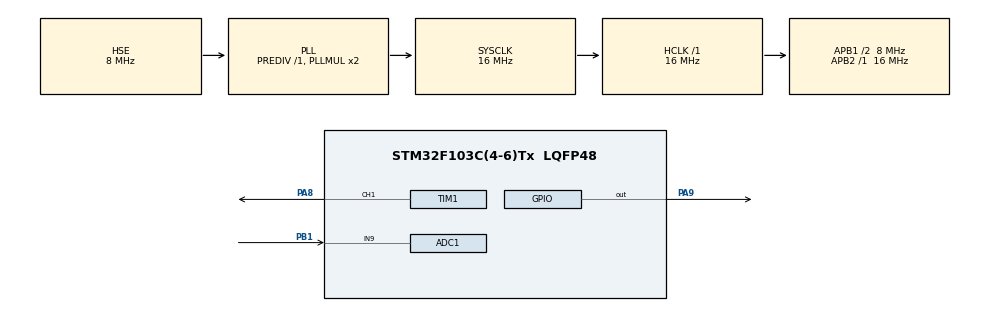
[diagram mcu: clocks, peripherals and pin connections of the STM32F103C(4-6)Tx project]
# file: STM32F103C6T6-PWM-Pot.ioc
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ADC1.Channel-4\#ChannelRegularConversion=ADC_CHANNEL_9
ADC1.ContinuousConvMode=ENABLE
ADC1.NbrOfConversion=1
ADC1.NbrOfConversionFlag=1
ADC1.Rank-4\#ChannelRegularConversion=1
ADC1.SamplingTime-4\#ChannelRegularConversion=ADC_SAMPLETIME_239CYCLES_5
ADC1.master=1
Dma.ADC1.0.Direction=DMA_PERIPH_TO_MEMORY
Dma.ADC1.0.Instance=DMA1_Channel1
Dma.ADC1.0.MemDataAlignment=DMA_MDATAALIGN_WORD
Dma.ADC1.0.MemInc=DMA_MINC_ENABLE
Dma.ADC1.0.Mode=DMA_CIRCULAR
Dma.ADC1.0.PeriphDataAlignment=DMA_PDATAALIGN_WORD
Dma.ADC1.0.PeriphInc=DMA_PINC_DISABLE
Dma.ADC1.0.Priority=DMA_PRIORITY_LOW
Dma.Request0=ADC1
Mcu.Family=STM32F1
Mcu.Name=STM32F103C(4-6)Tx
Mcu.Package=LQFP48
NVIC.DMA1_Channel1_IRQn=true\:0\:0\:false\:false\:true\:false\:true\:true
NVIC.PriorityGroup=NVIC_PRIORITYGROUP_4
PA13.Mode=Serial_Wire
PA13.Signal=SYS_JTMS-SWDIO
PA14.Mode=Serial_Wire
PA14.Signal=SYS_JTCK-SWCLK
PA8.Signal=S_TIM1_CH1
PA9.PinState=GPIO_PIN_SET
PA9.Signal=GPIO_Output
PB1.Signal=ADCx_IN9
PC14-OSC32_IN.Mode=LSE-External-Oscillator
PC14-OSC32_IN.Signal=RCC_OSC32_IN
PC15-OSC32_OUT.Mode=LSE-External-Oscillator
PC15-OSC32_OUT.Signal=RCC_OSC32_OUT
PD0-OSC_IN.Mode=HSE-External-Oscillator
PD0-OSC_IN.Signal=RCC_OSC_IN
PD1-OSC_OUT.Mode=HSE-External-Oscillator
PD1-OSC_OUT.Signal=RCC_OSC_OUT
ProjectManager.HeapSize=0x200
ProjectManager.StackSize=0x400
ProjectManager.TargetToolchain=CMake
RCC.AHBFreq_Value=16000000
RCC.APB1CLKDivider=RCC_HCLK_DIV2
RCC.APB1Freq_Value=8000000
RCC.APB1TimFreq_Value=16000000
RCC.APB2Freq_Value=16000000
RCC.APB2TimFreq_Value=16000000
RCC.HCLKFreq_Value=16000000
RCC.PLLSourceVirtual=RCC_PLLSOURCE_HSE
RCC.SYSCLKFreq_VALUE=16000000
RCC.SYSCLKSource=RCC_SYSCLKSOURCE_PLLCLK
RCC.USBFreq_Value=16000000
SH.ADCx_IN9.0=ADC1_IN9,IN9
SH.S_TIM1_CH1.0=TIM1_CH1,PWM Generation1 CH1
TIM1.Channel-PWM\ Generation1\ CH1=TIM_CHANNEL_1
TIM1.Period=999
TIM1.Prescaler=71
board=custom

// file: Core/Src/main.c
/* USER CODE BEGIN Header */
/**
  ******************************************************************************
  * @file           : main.c
  * @brief          : Main program body
  ******************************************************************************
  * @attention
  *
  * Copyright (c) 2026 STMicroelectronics.
  * All rights reserved.
  *
  * This software is licensed under terms that can be found in the LICENSE file
  * in the root directory of this software component.
  * If no LICENSE file comes with this software, it is provided AS-IS.
  *
  ******************************************************************************
  */
/* USER CODE END Header */
#include "main.h"

/* USER CODE BEGIN PD */
uint32_t adc_dma[1];
/* USER CODE END PD */

ADC_HandleTypeDef hadc1;
DMA_HandleTypeDef hdma_adc1;

TIM_HandleTypeDef htim1;

void SystemClock_Config(void);
static void MX_GPIO_Init(void);
static void MX_DMA_Init(void);
static void MX_TIM1_Init(void);
static void MX_ADC1_Init(void);

/* USER CODE BEGIN 0 */

// ADC dalgalanmalarina ve gurultuye karsi 16 olcum yapip ortalamasini aliyoruz
#define FILTER_SIZE 16

uint32_t sum = 0;
uint16_t buffer[FILTER_SIZE];
uint8_t indexx = 0;

uint16_t FilterADC(uint16_t adc)
{
    sum -= buffer[indexx];
    buffer[indexx] = adc;
    sum += adc;

    indexx++;
    if(indexx >= FILTER_SIZE)
        indexx = 0;

    return sum / FILTER_SIZE;
}

//ADC icin 1k Potansiyometre kullan 1k daha stabil 10k fazla ziplama yapiyor
void HAL_SYSTICK_Callback(void)
{
    uint16_t adc = FilterADC(adc_dma[0]);
    uint32_t ccr = (adc * 1000) / 4095;

    // Alt eşik: bu değerin altını tamamen 0 kabul et
    if (ccr < 5 )
        ccr = 0;

    __HAL_TIM_SET_COMPARE(&htim1, TIM_CHANNEL_1, ccr);
}

/* USER CODE END 0 */

int main(void)
{

  /* MCU Configuration--------------------------------------------------------*/

  /* Reset of all peripherals, Initializes the Flash interface and the Systick. */
  HAL_Init();

  /* Configure the system clock */
  SystemClock_Config();

  /* Initialize all configured peripherals */
  MX_GPIO_Init();
  MX_DMA_Init();
  MX_TIM1_Init();
  MX_ADC1_Init();
  /* USER CODE BEGIN 2 */

    // ------------ PWM --------------
    HAL_TIM_PWM_Start(&htim1, TIM_CHANNEL_1);
    //__HAL_TIM_SET_COMPARE(&htim1, TIM_CHANNEL_1, 70);

    ///----------- DMA -------------
    HAL_ADC_Start_DMA(&hadc1, adc_dma, 1);

  /* USER CODE END 2 */

  /* Infinite loop */
  while (1)
  {

    /* USER CODE BEGIN 3 */

     // HAL_GPIO_TogglePin(GPIOC, GPIO_PIN_13);
     // HAL_Delay(200);

  }
  /* USER CODE END 3 */
}

void SystemClock_Config(void)
{
  RCC_OscInitTypeDef RCC_OscInitStruct = {0};
  RCC_ClkInitTypeDef RCC_ClkInitStruct = {0};
  RCC_PeriphCLKInitTypeDef PeriphClkInit = {0};

  /** Initializes the RCC Oscillators according to the specified parameters
  * in the RCC_OscInitTypeDef structure.
  */
  RCC_OscInitStruct.OscillatorType = RCC_OSCILLATORTYPE_HSE;
  RCC_OscInitStruct.HSEState = RCC_HSE_ON;
  RCC_OscInitStruct.HSEPredivValue = RCC_HSE_PREDIV_DIV1;
  RCC_OscInitStruct.HSIState = RCC_HSI_ON;
  RCC_OscInitStruct.PLL.PLLState = RCC_PLL_ON;
  RCC_OscInitStruct.PLL.PLLSource = RCC_PLLSOURCE_HSE;
  RCC_OscInitStruct.PLL.PLLMUL = RCC_PLL_MUL2;
  if (HAL_RCC_OscConfig(&RCC_OscInitStruct) != HAL_OK)
  {
    Error_Handler();
  }

  /** Initializes the CPU, AHB and APB buses clocks
  */
  RCC_ClkInitStruct.ClockType = RCC_CLOCKTYPE_HCLK|RCC_CLOCKTYPE_SYSCLK
                              |RCC_CLOCKTYPE_PCLK1|RCC_CLOCKTYPE_PCLK2;
  RCC_ClkInitStruct.SYSCLKSource = RCC_SYSCLKSOURCE_PLLCLK;
  RCC_ClkInitStruct.AHBCLKDivider = RCC_SYSCLK_DIV1;
  RCC_ClkInitStruct.APB1CLKDivider = RCC_HCLK_DIV2;
  RCC_ClkInitStruct.APB2CLKDivider = RCC_HCLK_DIV1;

  if (HAL_RCC_ClockConfig(&RCC_ClkInitStruct, FLASH_LATENCY_0) != HAL_OK)
  {
    Error_Handler();
  }
  PeriphClkInit.PeriphClockSelection = RCC_PERIPHCLK_ADC;
  PeriphClkInit.AdcClockSelection = RCC_ADCPCLK2_DIV2;
  if (HAL_RCCEx_PeriphCLKConfig(&PeriphClkInit) != HAL_OK)
  {
    Error_Handler();
  }
}

static void MX_ADC1_Init(void)
{

  ADC_ChannelConfTypeDef sConfig = {0};

  /** Common config
  */
  hadc1.Instance = ADC1;
  hadc1.Init.ScanConvMode = ADC_SCAN_DISABLE;
  hadc1.Init.ContinuousConvMode = ENABLE;
  hadc1.Init.DiscontinuousConvMode = DISABLE;
  hadc1.Init.ExternalTrigConv = ADC_SOFTWARE_START;
  hadc1.Init.DataAlign = ADC_DATAALIGN_RIGHT;
  hadc1.Init.NbrOfConversion = 1;
  if (HAL_ADC_Init(&hadc1) != HAL_OK)
  {
    Error_Handler();
  }

  /** Configure Regular Channel
  */
  sConfig.Channel = ADC_CHANNEL_9;
  sConfig.Rank = ADC_REGULAR_RANK_1;
  sConfig.SamplingTime = ADC_SAMPLETIME_239CYCLES_5;
  if (HAL_ADC_ConfigChannel(&hadc1, &sConfig) != HAL_OK)
  {
    Error_Handler();
  }

}

static void MX_TIM1_Init(void)
{

  TIM_MasterConfigTypeDef sMasterConfig = {0};
  TIM_OC_InitTypeDef sConfigOC = {0};
  TIM_BreakDeadTimeConfigTypeDef sBreakDeadTimeConfig = {0};

  htim1.Instance = TIM1;
  htim1.Init.Prescaler = 71;
  htim1.Init.CounterMode = TIM_COUNTERMODE_UP;
  htim1.Init.Period = 999;
  htim1.Init.ClockDivision = TIM_CLOCKDIVISION_DIV1;
  htim1.Init.RepetitionCounter = 0;
  htim1.Init.AutoReloadPreload = TIM_AUTORELOAD_PRELOAD_DISABLE;
  if (HAL_TIM_PWM_Init(&htim1) != HAL_OK)
  {
    Error_Handler();
  }
  sMasterConfig.MasterOutputTrigger = TIM_TRGO_RESET;
  sMasterConfig.MasterSlaveMode = TIM_MASTERSLAVEMODE_DISABLE;
  if (HAL_TIMEx_MasterConfigSynchronization(&htim1, &sMasterConfig) != HAL_OK)
  {
    Error_Handler();
  }
  sConfigOC.OCMode = TIM_OCMODE_PWM1;
  sConfigOC.Pulse = 0;
  sConfigOC.OCPolarity = TIM_OCPOLARITY_HIGH;
  sConfigOC.OCNPolarity = TIM_OCNPOLARITY_HIGH;
  sConfigOC.OCFastMode = TIM_OCFAST_DISABLE;
  sConfigOC.OCIdleState = TIM_OCIDLESTATE_RESET;
  sConfigOC.OCNIdleState = TIM_OCNIDLESTATE_RESET;
  if (HAL_TIM_PWM_ConfigChannel(&htim1, &sConfigOC, TIM_CHANNEL_1) != HAL_OK)
  {
    Error_Handler();
  }
  sBreakDeadTimeConfig.OffStateRunMode = TIM_OSSR_DISABLE;
  sBreakDeadTimeConfig.OffStateIDLEMode = TIM_OSSI_DISABLE;
  sBreakDeadTimeConfig.LockLevel = TIM_LOCKLEVEL_OFF;
  sBreakDeadTimeConfig.DeadTime = 0;
  sBreakDeadTimeConfig.BreakState = TIM_BREAK_DISABLE;
  sBreakDeadTimeConfig.BreakPolarity = TIM_BREAKPOLARITY_HIGH;
  sBreakDeadTimeConfig.AutomaticOutput = TIM_AUTOMATICOUTPUT_DISABLE;
  if (HAL_TIMEx_ConfigBreakDeadTime(&htim1, &sBreakDeadTimeConfig) != HAL_OK)
  {
    Error_Handler();
  }
  HAL_TIM_MspPostInit(&htim1);

}

static void MX_DMA_Init(void)
{

  /* DMA controller clock enable */
  __HAL_RCC_DMA1_CLK_ENABLE();

  /* DMA interrupt init */
  /* DMA1_Channel1_IRQn interrupt configuration */
  HAL_NVIC_SetPriority(DMA1_Channel1_IRQn, 0, 0);
  HAL_NVIC_EnableIRQ(DMA1_Channel1_IRQn);

}

static void MX_GPIO_Init(void)
{
  GPIO_InitTypeDef GPIO_InitStruct = {0};

  /* GPIO Ports Clock Enable */
  __HAL_RCC_GPIOC_CLK_ENABLE();
  __HAL_RCC_GPIOD_CLK_ENABLE();
  __HAL_RCC_GPIOB_CLK_ENABLE();
  __HAL_RCC_GPIOA_CLK_ENABLE();

  /*Configure GPIO pin Output Level */
  HAL_GPIO_WritePin(GPIOA, GPIO_PIN_9, GPIO_PIN_SET);

  /*Configure GPIO pin : PA9 */
  GPIO_InitStruct.Pin = GPIO_PIN_9;
  GPIO_InitStruct.Mode = GPIO_MODE_OUTPUT_PP;
  GPIO_InitStruct.Pull = GPIO_NOPULL;
  GPIO_InitStruct.Speed = GPIO_SPEED_FREQ_LOW;
  HAL_GPIO_Init(GPIOA, &GPIO_InitStruct);

}

void Error_Handler(void)
{
  __disable_irq();
  while (1)
  {
  }
}
